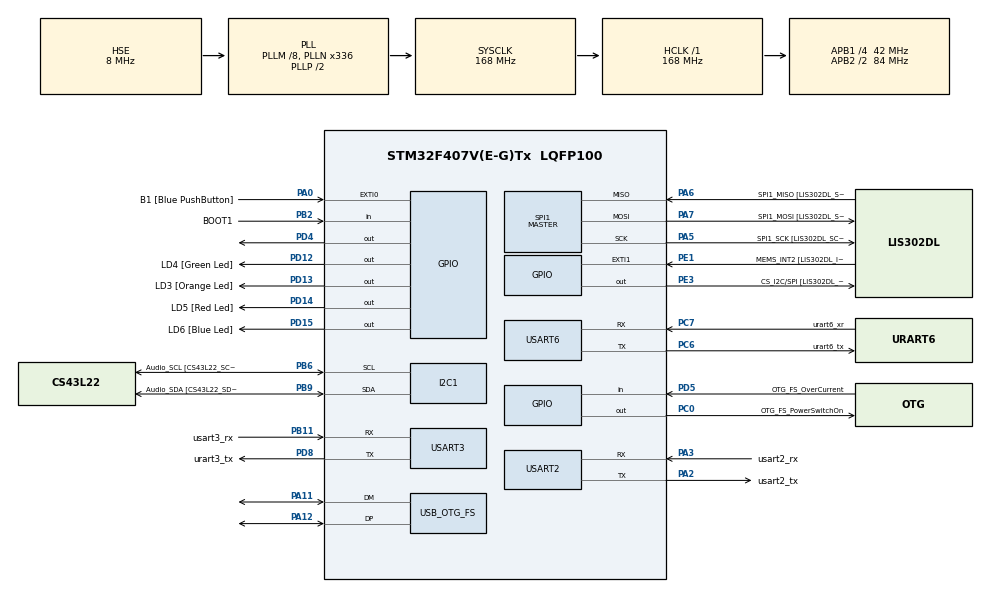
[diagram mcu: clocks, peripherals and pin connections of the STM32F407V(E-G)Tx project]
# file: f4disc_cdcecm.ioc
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PD12.GPIO_Label=LD4 [Green Led]
PH0-OSC_IN.Signal=RCC_OSC_IN
SPI1.VirtualType=VM_MASTER
Dma.USART3_TX.3.MemInc=DMA_MINC_ENABLE
Dma.USART6_TX.1.PeriphDataAlignment=DMA_PDATAALIGN_BYTE
PA14.GPIO_Label=SWCLK
Dma.USART2_TX.5.MemDataAlignment=DMA_MDATAALIGN_BYTE
PC6.GPIO_Label=urart6_tx
VP_RTC_VS_RTC_Activate.Mode=RTC_Enabled
PB6.GPIO_Label=Audio_SCL [CS43L22_SCL]
PA6.GPIO_Label=SPI1_MISO [LIS302DL_SDO]
Dma.USART3_TX.3.MemDataAlignment=DMA_MDATAALIGN_BYTE
Dma.USART2_RX.4.PeriphDataAlignment=DMA_PDATAALIGN_BYTE
PC15-OSC32_OUT.GPIO_Label=PC15-OSC32_OUT
RCC.SYSCLKSource=RCC_SYSCLKSOURCE_PLLCLK
PA6.GPIO_Mode=GPIO_MODE_AF_PP
Dma.USART3_RX.2.Priority=DMA_PRIORITY_LOW
PD14.GPIO_Speed=GPIO_SPEED_FREQ_LOW
Dma.USART6_RX.0.Instance=DMA2_Stream1
Dma.USART6_RX.0.FIFOMode=DMA_FIFOMODE_DISABLE
SPI1.Direction=SPI_DIRECTION_2LINES
PD4.Signal=GPIO_Output
RCC.APB2TimFreq_Value=168000000
PB6.Signal=I2C1_SCL
PC7.Signal=USART6_RX
PB6.Mode=I2C
PD8.Signal=USART3_TX
PE1.Signal=GPXTI1
NVIC.TIM8_TRG_COM_TIM14_IRQn=true\:0\:0\:false\:false\:true\:false\:true
PB2.Signal=GPIO_Input
PB3.Mode=Trace_Asynchronous_SW
PA5.GPIO_PuPd=GPIO_NOPULL
PD5.GPIO_Mode=GPIO_MODE_INPUT
PD14.GPIO_PuPd=GPIO_NOPULL
VP_SYS_VS_tim14.Mode=TIM14
PB2.GPIO_PuPd=GPIO_NOPULL
Dma.USART6_TX.1.PeriphInc=DMA_PINC_DISABLE
SPI1.CalculateBaudRate-Full_Duplex_Master=42.0 MBits/s
Dma.USART2_TX.5.Mode=DMA_NORMAL
Mcu.Package=LQFP100
PB9.Signal=I2C1_SDA
NVIC.TimeBase=TIM8_TRG_COM_TIM14_IRQn
PD12.Signal=GPIO_Output
NVIC.TimeBaseIP=TIM14
PB9.GPIO_PuPd=GPIO_NOPULL
RCC.APB2CLKDivider=RCC_HCLK_DIV2
RCC.APB1TimFreq_Value=84000000
Dma.USART6_TX.1.FIFOMode=DMA_FIFOMODE_DISABLE
PA6.GPIO_Speed=GPIO_SPEED_FREQ_LOW
NVIC.DMA1_Stream6_IRQn=true\:0\:0\:false\:false\:true\:false\:true
PD15.Signal=GPIO_Output
PC0.PinState=GPIO_PIN_SET
PA5.Mode=Full_Duplex_Master
Dma.USART6_TX.1.Instance=DMA2_Stream6
Dma.USART6_RX.0.PeriphInc=DMA_PINC_DISABLE
PB6.GPIO_PuPd=GPIO_NOPULL
PC6.Signal=USART6_TX
PB11.GPIO_Label=usart3_rx
PE1.GPIO_PuPd=GPIO_NOPULL
NVIC.DMA2_Stream1_IRQn=true\:0\:0\:false\:false\:true\:false\:true
PC0.Signal=GPIO_Output
RCC.APB1CLKDivider=RCC_HCLK_DIV4
PC14-OSC32_IN.Signal=RCC_OSC32_IN
PA0-WKUP.GPIO_ModeDefaultEXTI=GPIO_MODE_EVT_RISING
Dma.USART3_TX.3.PeriphInc=DMA_PINC_DISABLE
PA0-WKUP.GPIO_Label=B1 [Blue PushButton]
PA0-WKUP.Signal=GPXTI0
PA3.Mode=Asynchronous
Dma.USART3_RX.2.PeriphDataAlignment=DMA_PDATAALIGN_BYTE
PB11.Mode=Asynchronous
PC6.Mode=Asynchronous
NVIC.DMA2_Stream6_IRQn=true\:0\:0\:false\:false\:true\:false\:true
PD8.Mode=Asynchronous
PA5.Signal=SPI1_SCK
PE1.GPIO_Label=MEMS_INT2 [LIS302DL_INT2]
PA7.GPIO_Speed=GPIO_SPEED_FREQ_LOW
PB2.GPIO_Mode=GPIO_MODE_INPUT
SPI1.Mode=SPI_MODE_MASTER
Dma.USART2_TX.5.PeriphInc=DMA_PINC_DISABLE
PE3.GPIO_PuPd=GPIO_NOPULL
RCC.RCC_RTC_Clock_SourceVirtual=RCC_RTCCLKSOURCE_LSE
Dma.USART2_TX.5.FIFOMode=DMA_FIFOMODE_DISABLE
PH1-OSC_OUT.GPIO_Label=PH1-OSC_OUT
PA13.Mode=Trace_Asynchronous_SW
Dma.USART3_TX.3.Mode=DMA_NORMAL
Dma.USART6_TX.1.Direction=DMA_MEMORY_TO_PERIPH
PC7.GPIO_Label=urart6_xr
PA5.GPIO_Label=SPI1_SCK [LIS302DL_SCL/SPC]
Dma.USART2_RX.4.MemDataAlignment=DMA_MDATAALIGN_BYTE
PE3.GPIO_Speed=GPIO_SPEED_FREQ_LOW
Dma.USART2_TX.5.Instance=DMA1_Stream6
PA11.Signal=USB_OTG_FS_DM
ProjectManager.HeapSize=0x200
NVIC.PriorityGroup=NVIC_PRIORITYGROUP_4
Dma.USART6_RX.0.MemInc=DMA_MINC_ENABLE
PE3.Signal=GPIO_Output
PA0-WKUP.GPIO_PuPd=GPIO_NOPULL
Dma.USART2_RX.4.Mode=DMA_NORMAL
PB6.GPIO_Speed=GPIO_SPEED_FREQ_LOW
SPI1.BaudRatePrescaler-Full_Duplex_Master=SPI_BAUDRATEPRESCALER_2
Dma.USART3_TX.3.Priority=DMA_PRIORITY_LOW
Mcu.Family=STM32F4
NVIC.USART3_IRQn=true\:0\:0\:false\:false\:true\:true\:true
PA6.Mode=Full_Duplex_Master
USB_DEVICE.CLASS_NAME_FS=CDC
Dma.USART6_TX.1.MemInc=DMA_MINC_ENABLE
RCC.CortexFreq_Value=168000000
PB6.GPIO_Mode=GPIO_MODE_AF_OD
Dma.USART3_TX.3.PeriphDataAlignment=DMA_PDATAALIGN_BYTE
Dma.USART2_TX.5.MemInc=DMA_MINC_ENABLE
PD15.GPIO_Speed=GPIO_SPEED_FREQ_LOW
PA7.GPIO_Mode=GPIO_MODE_AF_PP
PC0.GPIO_Label=OTG_FS_PowerSwitchOn
PA11.Mode=Device_Only
USB_DEVICE.VirtualMode-CDC_FS=Cdc
Dma.USART2_RX.4.Instance=DMA1_Stream5
PB11.Signal=USART3_RX
Dma.USART6_TX.1.MemDataAlignment=DMA_MDATAALIGN_BYTE
ProjectManager.StackSize=0x400
SPI1.Mode-Full_Duplex_Master=SPI_MODE_MASTER
PD13.Signal=GPIO_Output
PA12.Signal=USB_OTG_FS_DP
Dma.USART6_RX.0.Direction=DMA_PERIPH_TO_MEMORY
RCC.RCC_RTC_Clock_Source=RCC_RTCCLKSOURCE_LSI
Dma.USART3_RX.2.PeriphInc=DMA_PINC_DISABLE
RCC.HCLKFreq_Value=168000000
RCC.AHBFreq_Value=168000000
PH0-OSC_IN.Mode=HSE-External-Oscillator
PH0-OSC_IN.GPIO_Label=PH0-OSC_IN
RCC.HSE_VALUE=8000000
PA6.GPIO_PuPd=GPIO_NOPULL
Dma.USART3_TX.3.Direction=DMA_MEMORY_TO_PERIPH
PC14-OSC32_IN.Mode=LSE-External-Oscillator
Dma.USART2_RX.4.FIFOMode=DMA_FIFOMODE_DISABLE
PA14.Mode=Trace_Asynchronous_SW
Dma.USART2_TX.5.PeriphDataAlignment=DMA_PDATAALIGN_BYTE
Dma.USART2_TX.5.Priority=DMA_PRIORITY_LOW
Dma.USART2_RX.4.Priority=DMA_PRIORITY_LOW
PH1-OSC_OUT.Mode=HSE-External-Oscillator
PD13.GPIO_Label=LD3 [Orange Led]
PA6.Signal=SPI1_MISO
USART2.VirtualMode=VM_ASYNC
USART6.VirtualMode=VM_ASYNC
PD5.GPIO_Label=OTG_FS_OverCurrent
NVIC.OTG_FS_IRQn=true\:0\:0\:false\:false\:true\:true\:true
PD15.GPIO_PuPd=GPIO_NOPULL
PA2.GPIO_Label=usart2_tx
Dma.USART2_RX.4.MemInc=DMA_MINC_ENABLE
Dma.USART6_RX.0.Mode=DMA_NORMAL
USB_OTG_FS.VirtualMode=Device_Only
Dma.USART6_RX.0.MemDataAlignment=DMA_MDATAALIGN_BYTE
PB9.GPIO_Speed=GPIO_SPEED_FREQ_LOW
Dma.Request2=USART3_RX
Dma.Request1=USART6_TX
Dma.Request4=USART2_RX
Dma.Request3=USART3_TX
Dma.Request5=USART2_TX
PC14-OSC32_IN.GPIO_Label=PC14-OSC32_IN
Dma.USART2_TX.5.Direction=DMA_MEMORY_TO_PERIPH
PC0.GPIO_PuPd=GPIO_NOPULL
Dma.Request0=USART6_RX
PA3.Signal=USART2_RX
PB3.GPIO_Label=SWO
PC15-OSC32_OUT.Mode=LSE-External-Oscillator
PD12.GPIO_Speed=GPIO_SPEED_FREQ_LOW
PD15.GPIO_Label=LD6 [Blue Led]
PA7.Mode=Full_Duplex_Master
PB9.GPIO_Label=Audio_SDA [CS43L22_SDA]
Dma.USART3_RX.2.Mode=DMA_NORMAL
USB_DEVICE.VirtualModeFS=Cdc_FS
PD5.Signal=GPIO_Input
NVIC.DMA1_Stream1_IRQn=true\:0\:0\:false\:false\:true\:false\:true
PE1.GPIO_ModeDefaultEXTI=GPIO_MODE_EVT_RISING
NVIC.USART2_IRQn=true\:0\:0\:false\:false\:true\:true\:true
NVIC.USART6_IRQn=true\:0\:0\:false\:false\:true\:true\:true
PD8.GPIO_Label=urart3_tx
PA13.Signal=SYS_JTMS-SWDIO
PC0.GPIO_Speed=GPIO_SPEED_FREQ_LOW
Dma.USART3_RX.2.MemInc=DMA_MINC_ENABLE
ProjectManager.TargetToolchain=Makefile
NVIC.DMA1_Stream5_IRQn=true\:0\:0\:false\:false\:true\:false\:true
VP_USB_DEVICE_VS_USB_DEVICE_CDC_FS.Mode=CDC_FS
PB9.Mode=I2C
Dma.USART3_TX.3.FIFOMode=DMA_FIFOMODE_DISABLE
Dma.USART6_TX.1.Priority=DMA_PRIORITY_LOW
Dma.USART3_RX.2.Direction=DMA_PERIPH_TO_MEMORY
PC15-OSC32_OUT.Signal=RCC_OSC32_OUT
PA7.GPIO_PuPd=GPIO_NOPULL
Dma.USART2_RX.4.PeriphInc=DMA_PINC_DISABLE
Dma.USART3_TX.3.Instance=DMA1_Stream3
board=STM32F407G-DISC1
PD13.GPIO_Speed=GPIO_SPEED_FREQ_LOW
RCC.VCOOutputFreq_Value=336000000
PB9.GPIO_Mode=GPIO_MODE_AF_OD
Dma.USART2_RX.4.Direction=DMA_PERIPH_TO_MEMORY
RCC.APB2Freq_Value=84000000
PH1-OSC_OUT.Signal=RCC_OSC_OUT
PD13.GPIO_PuPd=GPIO_NOPULL
PD5.GPIO_PuPd=GPIO_NOPULL
PD14.GPIO_Label=LD5 [Red Led]
Mcu.Name=STM32F407V(E-G)Tx
PA13.GPIO_Label=SWDIO
PA2.Signal=USART2_TX
PD14.Signal=GPIO_Output
RCC.48MHZClocksFreq_Value=48000000
PB3.Signal=SYS_JTDO-SWO
RCC.SYSCLKFreq_VALUE=168000000
Dma.USART6_RX.0.PeriphDataAlignment=DMA_PDATAALIGN_BYTE
PA7.GPIO_Label=SPI1_MOSI [LIS302DL_SDA/SDI/SDO]
PA12.Mode=Device_Only
USART3.VirtualMode=VM_ASYNC
PA14.Signal=SYS_JTCK-SWCLK
PB2.GPIO_Label=BOOT1
Dma.USART3_RX.2.FIFOMode=DMA_FIFOMODE_DISABLE
RCC.HSI_VALUE=16000000
Dma.USART6_RX.0.Priority=DMA_PRIORITY_LOW
PA5.GPIO_Speed=GPIO_SPEED_FREQ_LOW
RCC.PLLQ=7
Dma.USART3_RX.2.MemDataAlignment=DMA_MDATAALIGN_BYTE
RCC.PLLM=8
RCC.PLLN=336
PA2.Mode=Asynchronous
PE3.GPIO_Label=CS_I2C/SPI [LIS302DL_CS_I2C/SPI]
NVIC.DMA1_Stream3_IRQn=true\:0\:0\:false\:false\:true\:false\:true
Dma.USART3_RX.2.Instance=DMA1_Stream1
PC7.Mode=Asynchronous
RCC.APB1Freq_Value=42000000
PA5.GPIO_Mode=GPIO_MODE_AF_PP
Dma.USART6_TX.1.Mode=DMA_NORMAL
PD12.GPIO_PuPd=GPIO_NOPULL
PA3.GPIO_Label=usart2_rx
PA7.Signal=SPI1_MOSI

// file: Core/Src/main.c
/* USER CODE BEGIN Header */
/**
  ******************************************************************************
  * @file           : main.c
  * @brief          : Main program body
  ******************************************************************************
  * @attention
  *
  * <h2><center>&copy; Copyright (c) 2020 STMicroelectronics.
  * All rights reserved.</center></h2>
  *
  * This software component is licensed by ST under Ultimate Liberty license
  * SLA0044, the "License"; You may not use this file except in compliance with
  * the License. You may obtain a copy of the License at:
  *                             www.st.com/SLA0044
  *
  ******************************************************************************
  */
/* USER CODE END Header */

#include "main.h"
#include "dma.h"
#include "i2c.h"
#include "rtc.h"
#include "spi.h"
#include "usart.h"
#include "usb_device.h"
#include "gpio.h"

/* USER CODE BEGIN Includes */
#include "eth.h"
/* USER CODE END Includes */

void SystemClock_Config(void);

int main(void)
{

  /* MCU Configuration--------------------------------------------------------*/

  /* Reset of all peripherals, Initializes the Flash interface and the Systick. */
  HAL_Init();

  /* Configure the system clock */
  SystemClock_Config();

  /* Initialize all configured peripherals */
  MX_GPIO_Init();
  MX_DMA_Init();
  MX_I2C1_Init();
  MX_RTC_Init();
  MX_SPI1_Init();
  MX_USART2_UART_Init();
  MX_USART3_UART_Init();
  MX_USART6_UART_Init();
  MX_USB_DEVICE_Init();
  /* USER CODE BEGIN 2 */

  start_server();

  /* USER CODE END 2 */

  /* Infinite loop */
  while (1)
  {

  }
}

void SystemClock_Config(void)
{
  RCC_OscInitTypeDef RCC_OscInitStruct = {0};
  RCC_ClkInitTypeDef RCC_ClkInitStruct = {0};
  RCC_PeriphCLKInitTypeDef PeriphClkInitStruct = {0};

  /** Configure the main internal regulator output voltage
  */
  __HAL_RCC_PWR_CLK_ENABLE();
  __HAL_PWR_VOLTAGESCALING_CONFIG(PWR_REGULATOR_VOLTAGE_SCALE1);
  /** Initializes the CPU, AHB and APB busses clocks
  */
  RCC_OscInitStruct.OscillatorType = RCC_OSCILLATORTYPE_LSI|RCC_OSCILLATORTYPE_HSE;
  RCC_OscInitStruct.HSEState = RCC_HSE_ON;
  RCC_OscInitStruct.LSIState = RCC_LSI_ON;
  RCC_OscInitStruct.PLL.PLLState = RCC_PLL_ON;
  RCC_OscInitStruct.PLL.PLLSource = RCC_PLLSOURCE_HSE;
  RCC_OscInitStruct.PLL.PLLM = 8;
  RCC_OscInitStruct.PLL.PLLN = 336;
  RCC_OscInitStruct.PLL.PLLP = RCC_PLLP_DIV2;
  RCC_OscInitStruct.PLL.PLLQ = 7;
  if (HAL_RCC_OscConfig(&RCC_OscInitStruct) != HAL_OK)
  {
    Error_Handler();
  }
  /** Initializes the CPU, AHB and APB busses clocks
  */
  RCC_ClkInitStruct.ClockType = RCC_CLOCKTYPE_HCLK|RCC_CLOCKTYPE_SYSCLK
                              |RCC_CLOCKTYPE_PCLK1|RCC_CLOCKTYPE_PCLK2;
  RCC_ClkInitStruct.SYSCLKSource = RCC_SYSCLKSOURCE_PLLCLK;
  RCC_ClkInitStruct.AHBCLKDivider = RCC_SYSCLK_DIV1;
  RCC_ClkInitStruct.APB1CLKDivider = RCC_HCLK_DIV4;
  RCC_ClkInitStruct.APB2CLKDivider = RCC_HCLK_DIV2;

  if (HAL_RCC_ClockConfig(&RCC_ClkInitStruct, FLASH_LATENCY_5) != HAL_OK)
  {
    Error_Handler();
  }
  PeriphClkInitStruct.PeriphClockSelection = RCC_PERIPHCLK_RTC;
  PeriphClkInitStruct.RTCClockSelection = RCC_RTCCLKSOURCE_LSI;
  if (HAL_RCCEx_PeriphCLKConfig(&PeriphClkInitStruct) != HAL_OK)
  {
    Error_Handler();
  }
}

 /**
  * @brief  Period elapsed callback in non blocking mode
  * @note   This function is called  when TIM14 interrupt took place, inside
  * HAL_TIM_IRQHandler(). It makes a direct call to HAL_IncTick() to increment
  * a global variable "uwTick" used as application time base.
  * @param  htim : TIM handle
  * @retval None
  */
void HAL_TIM_PeriodElapsedCallback(TIM_HandleTypeDef *htim)
{
  if (htim->Instance == TIM14) {
    HAL_IncTick();
  }
}

void Error_Handler(void)
{
}

/************************ (C) COPYRIGHT STMicroelectronics *****END OF FILE****/
